AUTOSAR XML (schema 00049)
package /ComponentTypes
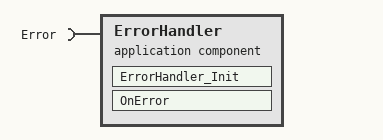
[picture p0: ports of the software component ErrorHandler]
  application sw component type ErrorHandler
    require port Error: nonqueued-receiver-com-spec{data-element=ErrorCode, filter=data-filter-type=ALWAYS}, required-interface=Error
    behavior ErrorHandler_InternalBehavior
      init event ErrorHandler_InitEvent: start-on-event=ErrorHandler_Init
      data received event DRT_OnError_Error_ErrorCode: start-on-event=OnError, data=Error.ErrorCode
      runnable ErrorHandler_Init
      runnable OnError
        data-receive-point-by-arguments:
          access REC_Error_ErrorCode: accessed-variable=Error.ErrorCode
  swc implementation ErrorHandler_Implementation: behavior=ErrorHandler_InternalBehavior
    code-descriptors:
      code Default: artifact-descriptors=autosar-engineering-object=category=SWSRC
